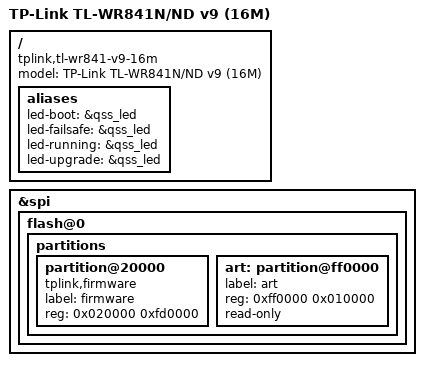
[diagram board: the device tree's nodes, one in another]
// SPDX-License-Identifier: GPL-2.0-or-later OR MIT
/dts-v1/;

#include "qca9533_tplink_tl-wr841-flashmod.dtsi"

/ {
	compatible = "tplink,tl-wr841-v9-16m", "qca,qca9533";
	model = "TP-Link TL-WR841N/ND v9 (16M)";

	aliases {
		led-boot = &qss_led;
		led-failsafe = &qss_led;
		led-running = &qss_led;
		led-upgrade = &qss_led;
	};
};

&spi {
	flash@0 {
		partitions {
			partition@20000 {
				compatible = "tplink,firmware";
				label = "firmware";
				reg = <0x020000 0xfd0000>;
			};

			art: partition@ff0000 {
				label = "art";
				reg = <0xff0000 0x010000>;
				read-only;
			};
		};
	};
};
